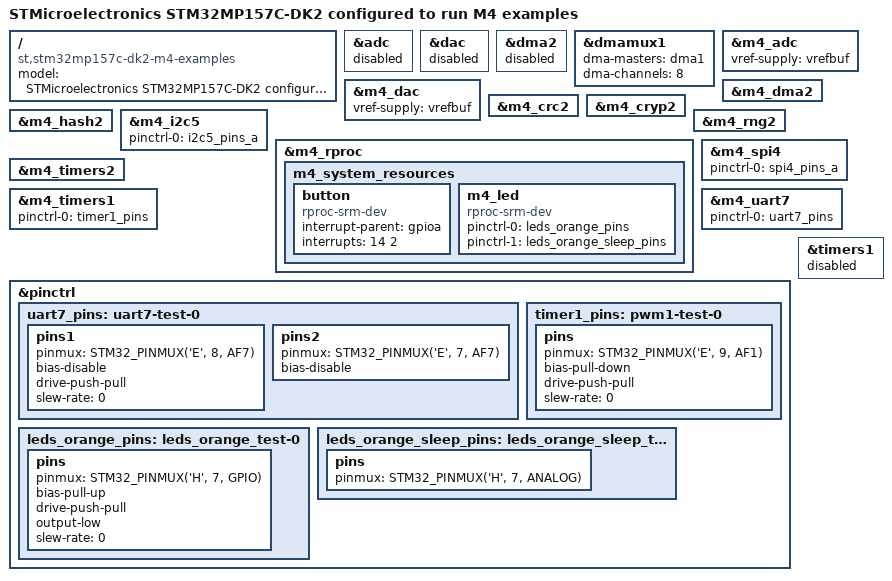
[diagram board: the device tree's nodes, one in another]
// SPDX-License-Identifier: (GPL-2.0+ OR BSD-3-Clause)
/*
 * Copyright (C) STMicroelectronics 2017 - All Rights Reserved
 * Author: Alexandre Torgue <alexandre.torgue@st.com> for STMicroelectronics.
 */

/dts-v1/;

#include "stm32mp157c-dk2.dts"

/ {
	model = "STMicroelectronics STM32MP157C-DK2 configured to run M4 examples";
	compatible = "st,stm32mp157c-dk2-m4-examples", "st,stm32mp157c-dk2", "st,stm32mp157";
};

&adc {
	status = "disabled";
};

&dac {
	status = "disabled";
};

&dma2 {
	status = "disabled";
};

&dmamux1 {
	dma-masters = <&dma1>;
	dma-channels = <8>;
};

&m4_adc {
	vref-supply = <&vrefbuf>;
	status = "okay";
};

&m4_dac {
	vref-supply = <&vrefbuf>;
	status = "okay";
};

&m4_dma2 {
	status = "okay";
};

&m4_crc2 {
	status = "okay";
};

&m4_cryp2 {
	status = "okay";
};

&m4_hash2 {
	status = "okay";
};

&m4_i2c5 {
	pinctrl-names = "rproc_default";
	pinctrl-0 = <&i2c5_pins_a>;
	status = "okay";
};

&m4_rng2 {
	status = "okay";
};

&m4_rproc {
	m4_system_resources {
		status = "okay";

		button {
			compatible = "rproc-srm-dev";
			interrupt-parent = <&gpioa>;
			interrupts = <14 2>;
			interrupt-names = "irq";
			status = "okay";
		};

		m4_led: m4_led {
			compatible = "rproc-srm-dev";
			pinctrl-names = "rproc_default", "rproc_sleep";
			pinctrl-0 = <&leds_orange_pins>;
			pinctrl-1 = <&leds_orange_sleep_pins>;
			status = "okay";
		};
	};
};

&m4_spi4 {
	pinctrl-names = "rproc_default";
	pinctrl-0 = <&spi4_pins_a>;
	status = "okay";
};


&m4_timers2 {
	pinctrl-names = "rproc_default";
	status = "okay";
};

&m4_timers1 {
	pinctrl-names = "rproc_default";
	pinctrl-0 = <&timer1_pins>;
	status = "okay";
};

&m4_uart7 {
	pinctrl-names = "rproc_default";
	pinctrl-0 = <&uart7_pins>;
	status = "okay";
};

&pinctrl {
	uart7_pins: uart7-test-0 {
		pins1 {
			pinmux = <STM32_PINMUX('E', 8, AF7)>; /* UART7_TX */
			bias-disable;
			drive-push-pull;
			slew-rate = <0>;
		};
		pins2 {
			pinmux = <STM32_PINMUX('E', 7, AF7)>; /* UART7_RX */
			bias-disable;
		};
	};

	timer1_pins: pwm1-test-0 {
		pins {
			pinmux = <STM32_PINMUX('E', 9, AF1)>; /* TIM1_CH1 */
			bias-pull-down;
			drive-push-pull;
			slew-rate = <0>;
		};
	};

	leds_orange_pins: leds_orange_test-0 {
		pins {
			pinmux = <STM32_PINMUX('H', 7, GPIO)>;
			bias-pull-up;
			drive-push-pull;
			output-low;
			slew-rate = <0>;
		};
	};

	leds_orange_sleep_pins: leds_orange_sleep_test-0 {
		pins {
			pinmux = <STM32_PINMUX('H', 7, ANALOG)>;
		};
	};
};

&timers1 {
	status = "disabled";
};
